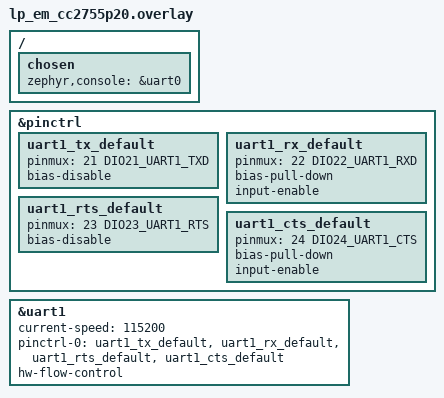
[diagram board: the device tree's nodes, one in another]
/*
 * SPDX-License-Identifier: Apache-2.0
 *
 * Copyright (c) Texas Instruments 2026
 */

#include <zephyr/dt-bindings/pinctrl/cc27xx-pinctrl.h>

&pinctrl {
	uart1_tx_default: uart1_tx_default {
		pinmux = <21 DIO21_UART1_TXD>;
		bias-disable;
	};

	uart1_rx_default: uart1_rx_default {
		pinmux = <22 DIO22_UART1_RXD>;
		bias-pull-down;
		input-enable;
	};

	uart1_rts_default: uart1_rts_default {
		pinmux = <23 DIO23_UART1_RTS>;
		bias-disable;
	};

	uart1_cts_default: uart1_cts_default {
		pinmux = <24 DIO24_UART1_CTS>;
		bias-pull-down;
		input-enable;
	};
};

/ {
	chosen {
		zephyr,console = &uart0;
	};
};

dut: &uart1 {
	current-speed = <115200>;
	pinctrl-0 = <&uart1_tx_default &uart1_rx_default
		     &uart1_rts_default &uart1_cts_default>;
	pinctrl-names = "default";
	hw-flow-control;
	status = "okay";
};
